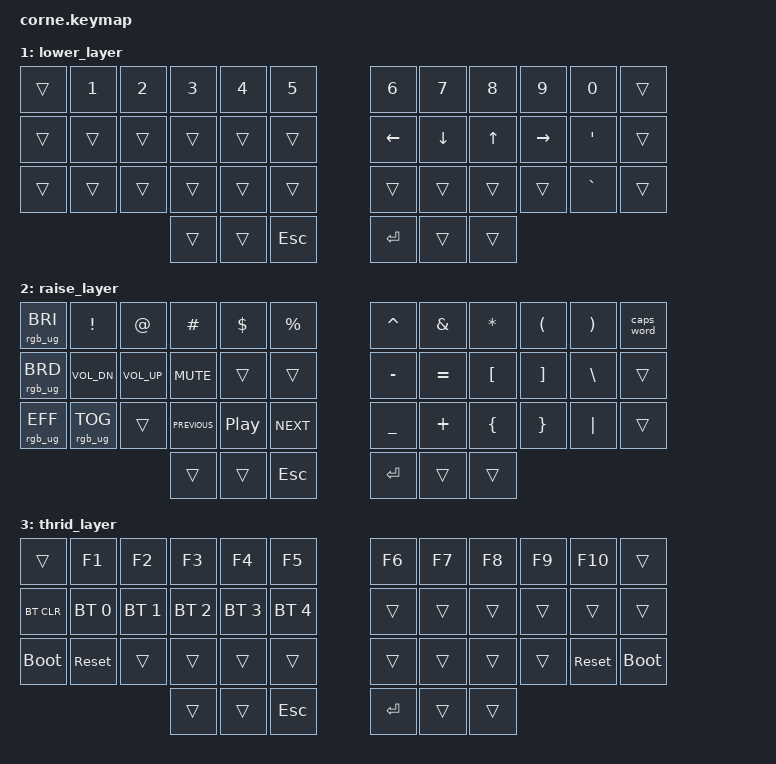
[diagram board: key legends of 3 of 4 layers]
/*
 * Copyright (c) 2020 The ZMK Contributors
 *
 * SPDX-License-Identifier: MIT
 */

#include <behaviors.dtsi>
#include <dt-bindings/zmk/keys.h>
#include <dt-bindings/zmk/bt.h>
#include <dt-bindings/zmk/rgb.h>
#include <dt-bindings/led/led.h>

&spi3 {
    compatible = "nordic,nrf-spim";
    status = "okay";

    pinctrl-0 = <&spi3_default>;
    pinctrl-1 = <&spi3_sleep>;
    pinctrl-names = "default", "sleep";

    led_strip: ws2812@0 {
        compatible = "worldsemi,ws2812-spi";

        /* SPI */
        reg = <0>; /* ignored, but necessary for SPI bindings */
        spi-max-frequency = <4000000>;

        /* WS2812 */
        chain-length = <27>; /* arbitrary; change at will */
        spi-one-frame = <0x70>;
        spi-zero-frame = <0x40>;

        color-mapping = <LED_COLOR_ID_GREEN LED_COLOR_ID_RED LED_COLOR_ID_BLUE>;
    };
};

/ {
    chosen {
        zmk,underglow = &led_strip;
    };
};



#define HRML(k1,k2,k3,k4) &ht LSHFT k1  &ht LALT k2  &ht LCTRL k3  &ht LGUI k4
#define HRMR(k1,k2,k3,k4) &ht RGUI k1  &ht RCTRL k2  &ht RALT k3  &ht RSHFT k4

/ {
      behaviors {
        ht: hold_tap {
            compatible = "zmk,behavior-hold-tap";
            #binding-cells = <2>;
            flavor = "tap-preferred";
            tapping-term-ms = <220>;
            quick-tap-ms = <150>;
            require-prior-idle-ms = <100>;
            bindings = <&kp>, <&kp>;
        };
    };
    // led_strip {
    //   chain-length = <27>;
    // };
      conditional_layers {
              compatible = "zmk,conditional-layers";
              tri_layer {
                if-layers = <1 2>;
                then-layer = <3>;
              };
        };
        keymap {
                compatible = "zmk,keymap";

                default_layer {
// -----------------------------------------------------------------------------------------
// |      |  Q  |  W  |  E  |  R  |  T  |   |  Y  |  U   |  I  |  O  |  P  |      |
// |      |  A  |  S  |  D  |  F  |  G  |   |  H  |  J   |  K  |  L  |  ;  |      |
// |      |  Z  |  X  |  C  |  V  |  B  |   |  N  |  M   |  ,  |  .  |  /  |      |
//                    |     | LWR | SPC |   | ENT | RSE  |     |
                        bindings = <
   &trans  &kp Q &kp W &kp E &kp R  &kp T           &kp Y &kp U  &kp I     &kp O   &kp P      &trans
   &trans HRML(A,  S,   D,    F) &kp G           &kp H HRMR(J,   K,    L,     SEMI)           &trans
   &trans   &kp Z &kp X &kp C &kp V &kp B          &kp N &kp M  &kp COMMA &kp DOT &kp FSLH    &trans
                  &trans &lt 1 TAB &kp SPACE    &kp RET &lt 2 BSPC &trans
                        >;
                };
                lower_layer {
// -----------------------------------------------------------------------------------------
// |      |  1  |  2  |  3  |  4  |  5  |   |  6  |  7  |  8  |  9  |  0  |      |
// |      |     |     |     |     |     |   | LFT | DWN |  UP | RGT |  '  |      |
// |      |     |     |     |     |     |   |     |     |     |     |  `  |      |
//                    |     |     | ESC |   | ENT |     |     |
                        bindings = <
   &trans  &kp N1       &kp N2       &kp N3       &kp N4       &kp N5         &kp N6   &kp N7   &kp N8 &kp N9    &kp N0  &trans
   &trans  &trans       &trans       &trans       &trans       &trans         &kp LEFT &kp DOWN &kp UP &kp RIGHT &kp SQT  &trans
   &trans  &trans       &trans       &trans       &trans       &trans         &trans   &trans   &trans &trans    &kp GRAVE &trans
                                     &trans       &trans       &kp ESC        &kp RET  &trans   &trans
                        >;
                };

                raise_layer {
// -----------------------------------------------------------------------------------------
// |      |  !  |  @  |  #  |  $  |  %  |   |  ^  |  &  |  *  |  (  |  )  |      |
// |      |     |     |     |     |     |   |  -  |  =  |  [  |  ]  |  \  |      |
// |      |     |     |     |     |     |   |  _  |  +  |  {  |  }  | "|" |      |
//                    |     |     | ESC |   | ENT |     |     |
                        bindings = <
   &rgb_ug RGB_BRI  &kp EXCL &kp AT &kp HASH &kp DLLR &kp PRCNT   &kp CARET &kp AMPS  &kp ASTRK &kp LPAR &kp RPAR &caps_word
   &rgb_ug RGB_BRD  &kp C_VOL_DN   &kp C_VOL_UP &kp C_MUTE   &trans   &trans      &kp MINUS &kp EQUAL &kp LBKT  &kp RBKT &kp BSLH &trans
   &rgb_ug RGB_EFF  &rgb_ug RGB_TOG   &trans &kp C_PREVIOUS   &kp C_PP   &kp C_NEXT      &kp UNDER &kp PLUS  &kp LBRC  &kp RBRC &kp PIPE &trans
                             &trans &trans   &kp ESC     &kp RET   &trans    &trans
                        >;
                };
                thrid_layer {
// -----------------------------------------------------------------------------------------
// |              | F1          |  F2 | F3  | F4  | F5  |   | F6  | F7  | F8  | F9  | F10         |            |
// | BTCLR        | BT1         | BT2 | BT3 | BT4 | BT5 |   | LFT | DWN |  UP | RGT |             |            |
// |  bootloader  |  sys_reset  |     |     |     |     |   |     |     |     |     |  sys_reset  | bootloader |
//                |             |     | ESC |               | ENT |     |     |
                        bindings = <
   &trans       &kp F1          &kp F2          &kp F3          &kp F4          &kp F5            &kp F6      &kp F7      &kp F8    &kp F9      &kp F10      &trans
   &bt BT_CLR   &bt BT_SEL 0    &bt BT_SEL 1    &bt BT_SEL 2    &bt BT_SEL 3    &bt BT_SEL 4      &trans      &trans      &trans    &trans      &trans      &trans
   &bootloader  &sys_reset      &trans          &trans          &trans          &trans            &trans      &trans      &trans    &trans      &sys_reset  &bootloader
                                &trans          &trans          &kp ESC                           &kp RET     &trans      &trans
                        >;
                };
        };
};

